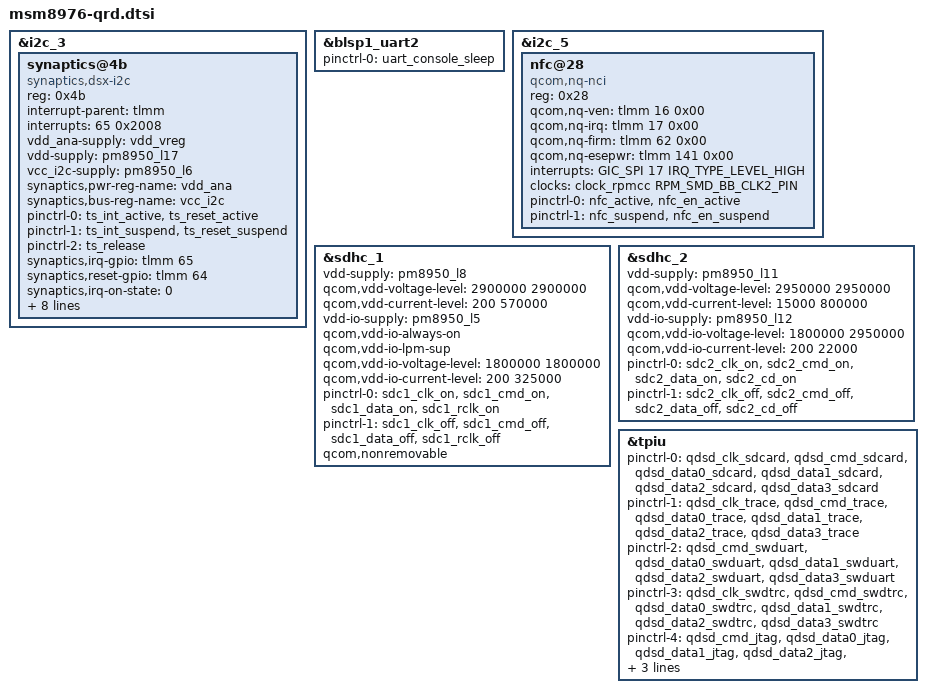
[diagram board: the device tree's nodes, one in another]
// SPDX-License-Identifier: GPL-2.0
// Copyright (c) 2015, The Linux Foundation. All rights reserved.
// Copyright (c) 2023-2024, Benarji Anand <benarji385@gmail.com>

#include "msm8976-camera-sensor-qrd.dtsi"

&i2c_3 { /* BLSP1 QUP3 */
	status = "okay";
	synaptics@4b {
		compatible = "synaptics,dsx-i2c";
		reg = <0x4b>;
		interrupt-parent = <&tlmm>;
		interrupts = <65 0x2008>;
		vdd_ana-supply = <&vdd_vreg>;
		vdd-supply = <&pm8950_l17>;
		vcc_i2c-supply = <&pm8950_l6>;
		synaptics,pwr-reg-name = "vdd_ana";
		synaptics,bus-reg-name = "vcc_i2c";
		/* pins used by touchscreen */
		pinctrl-names = "pmx_ts_active","pmx_ts_suspend","pmx_ts_release";
		pinctrl-0 = <&ts_int_active &ts_reset_active>;
		pinctrl-1 = <&ts_int_suspend &ts_reset_suspend>;
		pinctrl-2 = <&ts_release>;
		synaptics,irq-gpio = <&tlmm 65 0x2008>;
		synaptics,reset-gpio = <&tlmm 64 0x0>;
		synaptics,irq-on-state = <0>;
		synaptics,irq-flags = <0x2008>;
		synaptics,power-delay-ms = <200>;
		synaptics,reset-delay-ms = <200>;
		synaptics,max-y-for-2d = <1919>;
		synaptics,cap-button-codes = <139 158 172>;
		synaptics,vir-button-codes = <139 180 2000 320 160
					      158 540 2000 320 160
					      172 900 2000 320 160>;
		synaptics,resume-in-workqueue;
	};
};

&blsp1_uart2 {
        status = "ok";
        pinctrl-names = "default";
        pinctrl-0 = <&uart_console_sleep>;
};

&i2c_5 { /* BLSP2 QUP1 (NFC) */
	status = "okay";
	nfc@28 {
		compatible = "qcom,nq-nci";
		reg = <0x28>;
		qcom,nq-ven = <&tlmm 16 0x00>;
		qcom,nq-irq = <&tlmm 17 0x00>;
		qcom,nq-firm = <&tlmm 62 0x00>;
		qcom,nq-esepwr = <&tlmm 141 0x00>;
		interrupts = <GIC_SPI 17 IRQ_TYPE_LEVEL_HIGH>;
		interrupt-names = "nfc_irq";

		clocks = <&clock_rpmcc RPM_SMD_BB_CLK2_PIN>;
		clock-names = "ref_clk";

		pinctrl-names = "nfc_active", "nfc_suspend";
		pinctrl-0 = <&nfc_active &nfc_en_active>;
		pinctrl-1 = <&nfc_suspend &nfc_en_suspend>;
	};
};

&sdhc_1 {
	vdd-supply = <&pm8950_l8>;
	qcom,vdd-voltage-level = <2900000 2900000>;
	qcom,vdd-current-level = <200 570000>;

	vdd-io-supply = <&pm8950_l5>;
	qcom,vdd-io-always-on;
	qcom,vdd-io-lpm-sup;
	qcom,vdd-io-voltage-level = <1800000 1800000>;
	qcom,vdd-io-current-level = <200 325000>;

	pinctrl-names = "active", "sleep";
	pinctrl-0 = <&sdc1_clk_on &sdc1_cmd_on &sdc1_data_on &sdc1_rclk_on>;
	pinctrl-1 = <&sdc1_clk_off &sdc1_cmd_off &sdc1_data_off &sdc1_rclk_off>;

	qcom,nonremovable;

	status = "ok";
};

&sdhc_2 {
	vdd-supply = <&pm8950_l11>;
	qcom,vdd-voltage-level = <2950000 2950000>;
	qcom,vdd-current-level = <15000 800000>;

	vdd-io-supply = <&pm8950_l12>;
	qcom,vdd-io-voltage-level = <1800000 2950000>;
	qcom,vdd-io-current-level = <200 22000>;

	pinctrl-names = "active", "sleep";
	pinctrl-0 = <&sdc2_clk_on &sdc2_cmd_on &sdc2_data_on &sdc2_cd_on>;
	pinctrl-1 = <&sdc2_clk_off &sdc2_cmd_off &sdc2_data_off &sdc2_cd_off>;

	status = "ok";
};

/* CoreSight */
&tpiu {
	pinctrl-names = "sdcard", "trace", "swduart",
			"swdtrc", "jtag", "spmi";
	/* NIDnT */
	pinctrl-0 = <&qdsd_clk_sdcard &qdsd_cmd_sdcard
		     &qdsd_data0_sdcard &qdsd_data1_sdcard
		     &qdsd_data2_sdcard &qdsd_data3_sdcard>;
	pinctrl-1 = <&qdsd_clk_trace &qdsd_cmd_trace
		     &qdsd_data0_trace &qdsd_data1_trace
		     &qdsd_data2_trace &qdsd_data3_trace>;
	pinctrl-2 = <&qdsd_cmd_swduart &qdsd_data0_swduart
		     &qdsd_data1_swduart &qdsd_data2_swduart
		     &qdsd_data3_swduart>;
	pinctrl-3 = <&qdsd_clk_swdtrc &qdsd_cmd_swdtrc
		     &qdsd_data0_swdtrc &qdsd_data1_swdtrc
		     &qdsd_data2_swdtrc &qdsd_data3_swdtrc>;
	pinctrl-4 = <&qdsd_cmd_jtag &qdsd_data0_jtag
		     &qdsd_data1_jtag &qdsd_data2_jtag
		     &qdsd_data3_jtag>;
	pinctrl-5 = <&qdsd_clk_spmi &qdsd_cmd_spmi
		     &qdsd_data0_spmi &qdsd_data3_spmi>;
};
